# STM32F7x register map
File version: 1.1 AdaCore modified
Registers are 32-bit, read-write, reset 0x0 unless marked. A register's access mark holds for its fields unless they carry their own. Offsets are from the block's base; [hi:lo] are bit positions; {n}, {i} and the like mark numbered series.

## RCC — Reset and clock control
Base 0x40023800
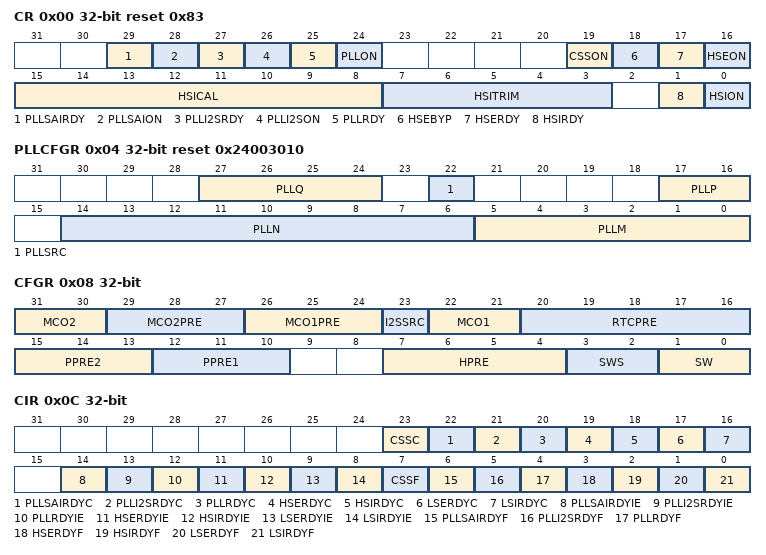
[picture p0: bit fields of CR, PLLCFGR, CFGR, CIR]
0x00 CR access per field reset 0x83 — clock control register
  [29] PLLSAIRDY ro — PLLSAI clock ready flag
  [28] PLLSAION rw — PLLSAI enable
  [27] PLLI2SRDY ro — PLLI2S clock ready flag
  [26] PLLI2SON rw — PLLI2S enable
  [25] PLLRDY ro — Main PLL (PLL) clock ready flag
  [24] PLLON rw — Main PLL (PLL) enable
  [19] CSSON rw — Clock security system enable
  [18] HSEBYP rw — HSE clock bypass
  [17] HSERDY ro — HSE clock ready flag
  [16] HSEON rw — HSE clock enable
  [15:8] HSICAL ro — Internal high-speed clock calibration
  [7:3] HSITRIM rw — Internal high-speed clock trimming
  [1] HSIRDY ro — Internal high-speed clock ready flag
  [0] HSION rw — Internal high-speed clock enable
0x04 PLLCFGR reset 0x24003010 — PLL configuration register
  [27:24] PLLQ — Main PLL (PLL) division factor for USB OTG FS, SDIO and random number generator clocks
  [22] PLLSRC — Main PLL(PLL) and audio PLL (PLLI2S) entry clock source
  [17:16] PLLP — Main PLL (PLL) division factor for main system clock
  [14:6] PLLN — Main PLL (PLL) multiplication factor for VCO
  [5:0] PLLM — Division factor for the main PLL (PLL) and audio PLL (PLLI2S) input clock
0x08 CFGR access per field — clock configuration register
  [31:30] MCO2 rw — Microcontroller clock output 2
  [29:27] MCO2PRE rw — MCO2 prescaler
  [26:24] MCO1PRE rw — MCO1 prescaler
  [23] I2SSRC rw — I2S clock selection
  [22:21] MCO1 rw — Microcontroller clock output 1
  [20:16] RTCPRE rw — HSE division factor for RTC clock
  [15:13] PPRE2 rw — APB high-speed prescaler (APB2)
  [12:10] PPRE1 rw — APB Low speed prescaler (APB1)
  [7:4] HPRE rw — AHB prescaler
  [3:2] SWS ro — System clock switch status
  [1:0] SW rw — System clock switch
0x0C CIR access per field — clock interrupt register
  [23] CSSC wo — Clock security system interrupt clear
  [22] PLLSAIRDYC wo — PLLSAI Ready Interrupt Clear
  [21] PLLI2SRDYC wo — PLLI2S ready interrupt clear
  [20] PLLRDYC wo — Main PLL(PLL) ready interrupt clear
  [19] HSERDYC wo — HSE ready interrupt clear
  [18] HSIRDYC wo — HSI ready interrupt clear
  [17] LSERDYC wo — LSE ready interrupt clear
  [16] LSIRDYC wo — LSI ready interrupt clear
  [14] PLLSAIRDYIE rw — PLLSAI Ready Interrupt Enable
  [13] PLLI2SRDYIE rw — PLLI2S ready interrupt enable
  [12] PLLRDYIE rw — Main PLL (PLL) ready interrupt enable
  [11] HSERDYIE rw — HSE ready interrupt enable
  [10] HSIRDYIE rw — HSI ready interrupt enable
  [9] LSERDYIE rw — LSE ready interrupt enable
  [8] LSIRDYIE rw — LSI ready interrupt enable
  [7] CSSF ro — Clock security system interrupt flag
  [6] PLLSAIRDYF ro — PLLSAI ready interrupt flag
  [5] PLLI2SRDYF ro — PLLI2S ready interrupt flag
  [4] PLLRDYF ro — Main PLL (PLL) ready interrupt flag
  [3] HSERDYF ro — HSE ready interrupt flag
  [2] HSIRDYF ro — HSI ready interrupt flag
  [1] LSERDYF ro — LSE ready interrupt flag
  [0] LSIRDYF ro — LSI ready interrupt flag
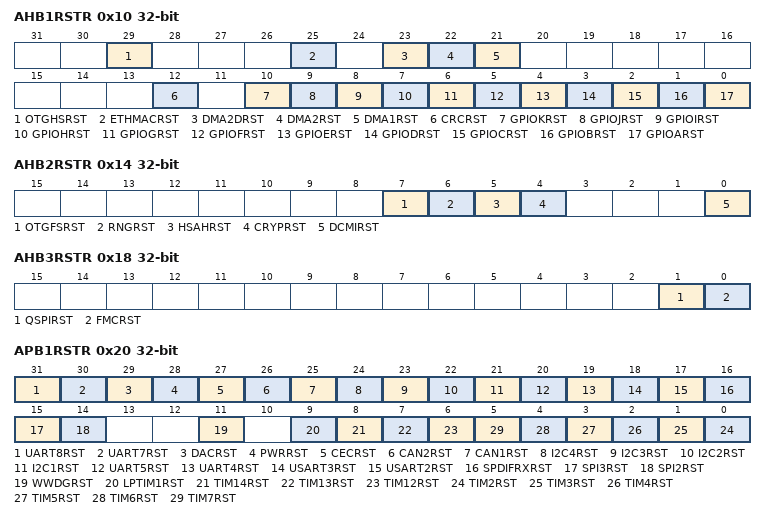
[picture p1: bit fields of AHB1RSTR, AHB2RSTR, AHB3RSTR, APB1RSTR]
0x10 AHB1RSTR — AHB1 peripheral reset register
  [29] OTGHSRST — USB OTG HS module reset
  [25] ETHMACRST — Ethernet MAC reset
  [23] DMA2DRST — DMA2D reset
  [22] DMA2RST — DMA2 reset
  [21] DMA1RST — DMA2 reset
  [12] CRCRST — CRC reset
  [10] GPIOKRST — IO port K reset
  [9] GPIOJRST — IO port J reset
  [8] GPIOIRST — IO port I reset
  [7] GPIOHRST — IO port H reset
  [6] GPIOGRST — IO port G reset
  [5] GPIOFRST — IO port F reset
  [4] GPIOERST — IO port E reset
  [3] GPIODRST — IO port D reset
  [2] GPIOCRST — IO port C reset
  [1] GPIOBRST — IO port B reset
  [0] GPIOARST — IO port A reset
0x14 AHB2RSTR — AHB2 peripheral reset register
  [7] OTGFSRST — USB OTG FS module reset
  [6] RNGRST — Random number generator module reset
  [5] HSAHRST — Hash module reset
  [4] CRYPRST — Cryptographic module reset
  [0] DCMIRST — Camera interface reset
0x18 AHB3RSTR — AHB3 peripheral reset register
  [1] QSPIRST — Quad SPI memory controller reset
  [0] FMCRST — Flexible memory controller module reset
0x20 APB1RSTR — APB1 peripheral reset register
  [31] UART8RST — UART8 reset
  [30] UART7RST — UART7 reset
  [29] DACRST — DAC reset
  [28] PWRRST — Power interface reset
  [27] CECRST — HDMI-CEC reset
  [26] CAN2RST — CAN2 reset
  [25] CAN1RST — CAN1 reset
  [24] I2C4RST — I2C 4 reset
  [23] I2C3RST — I2C3 reset
  [22] I2C2RST — I2C 2 reset
  [21] I2C1RST — I2C 1 reset
  [20] UART5RST — USART 5 reset
  [19] UART4RST — USART 4 reset
  [18] USART3RST — USART 3 reset
  [17] USART2RST — USART 2 reset
  [16] SPDIFRXRST — SPDIF-RX reset
  [15] SPI3RST — SPI 3 reset
  [14] SPI2RST — SPI 2 reset
  [11] WWDGRST — Window watchdog reset
  [9] LPTIM1RST — Low power timer 1 reset
  [8] TIM14RST — TIM14 reset
  [7] TIM13RST — TIM13 reset
  [6] TIM12RST — TIM12 reset
  [n-2] TIM{n}RST (n=2..7) — TIM{n} reset
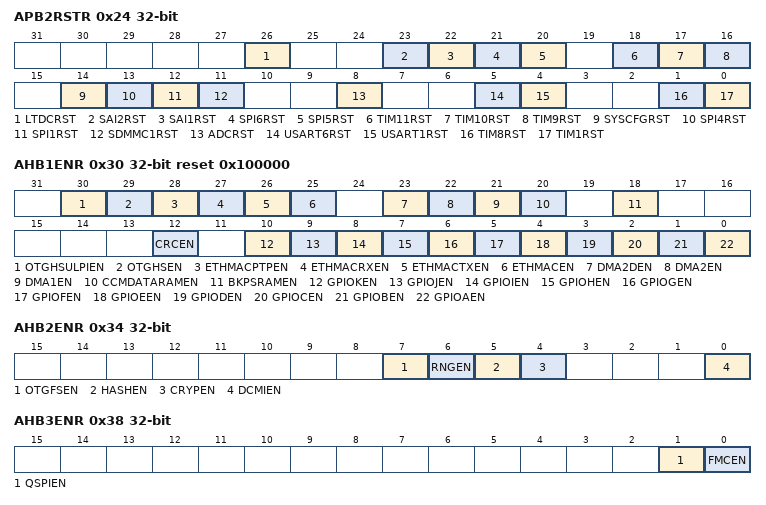
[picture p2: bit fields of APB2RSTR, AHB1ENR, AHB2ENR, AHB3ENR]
0x24 APB2RSTR — APB2 peripheral reset register
  [26] LTDCRST — LTDC reset
  [23] SAI2RST — SAI2 reset
  [22] SAI1RST — SAI1 reset
  [21] SPI6RST — SPI6 reset
  [20] SPI5RST — SPI5 reset
  [18] TIM11RST — TIM11 reset
  [17] TIM10RST — TIM10 reset
  [16] TIM9RST — TIM9 reset
  [14] SYSCFGRST — System configuration controller reset
  [13] SPI4RST — SPI4 reset
  [12] SPI1RST — SPI 1 reset
  [11] SDMMC1RST — SDMMC1 reset
  [8] ADCRST — ADC interface reset (common to all ADCs)
  [5] USART6RST — USART6 reset
  [4] USART1RST — USART1 reset
  [1] TIM8RST — TIM8 reset
  [0] TIM1RST — TIM1 reset
0x30 AHB1ENR reset 0x100000 — AHB1 peripheral clock register
  [30] OTGHSULPIEN — USB OTG HSULPI clock enable
  [29] OTGHSEN — USB OTG HS clock enable
    0=Disabled; 1=Enabled
  [28] ETHMACPTPEN — Ethernet PTP clock enable
    0=Disabled; 1=Enabled
  [27] ETHMACRXEN — Ethernet Reception clock enable
    0=Disabled; 1=Enabled
  [26] ETHMACTXEN — Ethernet Transmission clock enable
    0=Disabled; 1=Enabled
  [25] ETHMACEN — Ethernet MAC clock enable
    0=Disabled; 1=Enabled
  [23] DMA2DEN — DMA2D clock enable
  [22] DMA2EN — DMA2 clock enable
    0=Disabled; 1=Enabled
  [21] DMA1EN — DMA1 clock enable
    0=Disabled; 1=Enabled
  [20] CCMDATARAMEN — CCM data RAM clock enable
    0=Disabled; 1=Enabled
  [18] BKPSRAMEN — Backup SRAM interface clock enable
    0=Disabled; 1=Enabled
  [12] CRCEN — CRC clock enable
    0=Disabled; 1=Enabled
  [10] GPIOKEN — IO port K clock enable
    0=Disabled; 1=Enabled
  [9] GPIOJEN — IO port J clock enable
    0=Disabled; 1=Enabled
  [8] GPIOIEN — IO port I clock enable
    0=Disabled; 1=Enabled
  [7] GPIOHEN — IO port H clock enable
    0=Disabled; 1=Enabled
  [6] GPIOGEN — IO port G clock enable
    0=Disabled; 1=Enabled
  [5] GPIOFEN — IO port F clock enable
    0=Disabled; 1=Enabled
  [4] GPIOEEN — IO port E clock enable
    0=Disabled; 1=Enabled
  [3] GPIODEN — IO port D clock enable
    0=Disabled; 1=Enabled
  [2] GPIOCEN — IO port C clock enable
    0=Disabled; 1=Enabled
  [1] GPIOBEN — IO port B clock enable
    0=Disabled; 1=Enabled
  [0] GPIOAEN — IO port A clock enable
    0=Disabled; 1=Enabled
0x34 AHB2ENR — AHB2 peripheral clock enable register
  [all] fields
    0=Disabled; 1=Enabled
  [7] OTGFSEN — USB OTG FS clock enable
  [6] RNGEN — Random number generator clock enable
  [5] HASHEN — Hash modules clock enable
  [4] CRYPEN — Cryptographic modules clock enable
  [0] DCMIEN — Camera interface enable
0x38 AHB3ENR — AHB3 peripheral clock enable register
  [1] QSPIEN — Quad SPI memory controller clock enable
    0=Disabled; 1=Enabled
  [0] FMCEN — Flexible memory controller module clock enable
    0=Disabled; 1=Enabled
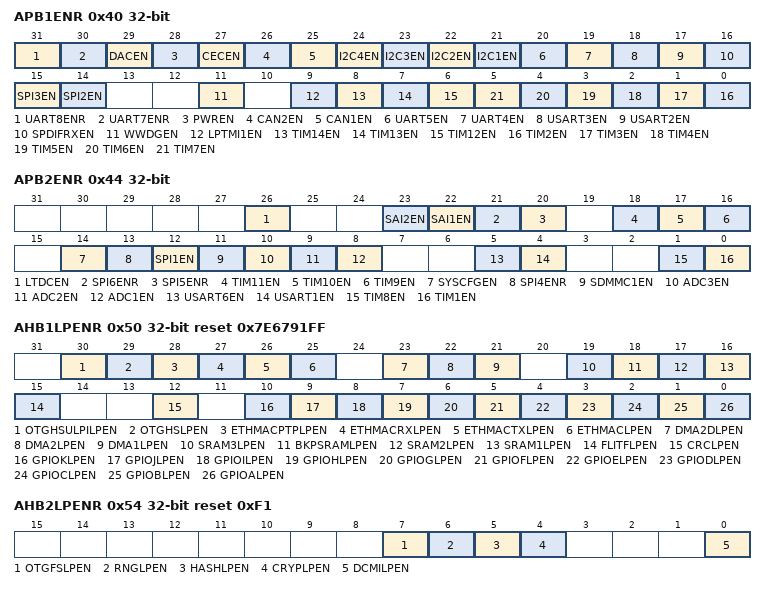
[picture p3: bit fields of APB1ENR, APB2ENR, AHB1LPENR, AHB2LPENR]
0x40 APB1ENR — APB1 peripheral clock enable register
  [all] fields
    0=Disabled; 1=Enabled
  [31] UART8ENR — UART8 clock enable
  [30] UART7ENR — UART7 clock enable
  [29] DACEN — DAC interface clock enable
  [28] PWREN — Power interface clock enable
  [27] CECEN — HDMI-CEN clock enable
  [26] CAN2EN — CAN 2 clock enable
  [25] CAN1EN — CAN 1 clock enable
  [n+20] I2C{n}EN (n=1..4) — I2C{n} clock enable
  [20] UART5EN — UART5 clock enable
  [19] UART4EN — UART4 clock enable
  [18] USART3EN — USART3 clock enable
  [17] USART2EN — USART 2 clock enable
  [16] SPDIFRXEN — SPDIF-RX clock enable
  [15] SPI3EN — SPI3 clock enable
  [14] SPI2EN — SPI2 clock enable
  [11] WWDGEN — Window watchdog clock enable
  [9] LPTMI1EN — Low power timer 1 clock enable
  [8] TIM14EN — TIM14 clock enable
  [7] TIM13EN — TIM13 clock enable
  [6] TIM12EN — TIM12 clock enable
  [n-2] TIM{n}EN (n=2..7) — TIM{n} clock enable
0x44 APB2ENR — APB2 peripheral clock enable register
  [all] fields
    0=Disabled; 1=Enabled
  [26] LTDCEN — LTDC clock enable
  [23] SAI2EN — SAI2 clock enable
  [22] SAI1EN — SAI1 clock enable
  [21] SPI6ENR — SPI6 clock enable
  [20] SPI5ENR — SPI5 clock enable
  [18] TIM11EN — TIM11 clock enable
  [17] TIM10EN — TIM10 clock enable
  [16] TIM9EN — TIM9 clock enable
  [14] SYSCFGEN — System configuration controller clock enable
  [13] SPI4ENR — SPI4 clock enable
  [12] SPI1EN — SPI1 clock enable
  [11] SDMMC1EN — SDMMC1 clock enable
  [10] ADC3EN — ADC3 clock enable
  [9] ADC2EN — ADC2 clock enable
  [8] ADC1EN — ADC1 clock enable
  [5] USART6EN — USART6 clock enable
  [4] USART1EN — USART1 clock enable
  [1] TIM8EN — TIM8 clock enable
  [0] TIM1EN — TIM1 clock enable
0x50 AHB1LPENR reset 0x7E6791FF — AHB1 peripheral clock enable in low power mode register
  [30] OTGHSULPILPEN — USB OTG HS ULPI clock enable during Sleep mode
  [29] OTGHSLPEN — USB OTG HS clock enable during Sleep mode
  [28] ETHMACPTPLPEN — Ethernet PTP clock enable during Sleep mode
  [27] ETHMACRXLPEN — Ethernet reception clock enable during Sleep mode
  [26] ETHMACTXLPEN — Ethernet transmission clock enable during Sleep mode
  [25] ETHMACLPEN — Ethernet MAC clock enable during Sleep mode
  [23] DMA2DLPEN — DMA2D clock enable during Sleep mode
  [22] DMA2LPEN — DMA2 clock enable during Sleep mode
  [21] DMA1LPEN — DMA1 clock enable during Sleep mode
  [19] SRAM3LPEN — SRAM 3 interface clock enable during Sleep mode
  [18] BKPSRAMLPEN — Backup SRAM interface clock enable during Sleep mode
  [17] SRAM2LPEN — SRAM 2 interface clock enable during Sleep mode
  [16] SRAM1LPEN — SRAM 1interface clock enable during Sleep mode
  [15] FLITFLPEN — Flash interface clock enable during Sleep mode
  [12] CRCLPEN — CRC clock enable during Sleep mode
  [10] GPIOKLPEN — IO port K clock enable during Sleep mode
  [9] GPIOJLPEN — IO port J clock enable during Sleep mode
  [8] GPIOILPEN — IO port I clock enable during Sleep mode
  [7] GPIOHLPEN — IO port H clock enable during Sleep mode
  [6] GPIOGLPEN — IO port G clock enable during Sleep mode
  [5] GPIOFLPEN — IO port F clock enable during Sleep mode
  [4] GPIOELPEN — IO port E clock enable during Sleep mode
  [3] GPIODLPEN — IO port D clock enable during Sleep mode
  [2] GPIOCLPEN — IO port C clock enable during Sleep mode
  [1] GPIOBLPEN — IO port B clock enable during Sleep mode
  [0] GPIOALPEN — IO port A clock enable during sleep mode
0x54 AHB2LPENR reset 0xF1 — AHB2 peripheral clock enable in low power mode register
  [7] OTGFSLPEN — USB OTG FS clock enable during Sleep mode
  [6] RNGLPEN — Random number generator clock enable during Sleep mode
  [5] HASHLPEN — Hash modules clock enable during Sleep mode
  [4] CRYPLPEN — Cryptography modules clock enable during Sleep mode
  [0] DCMILPEN — Camera interface enable during Sleep mode
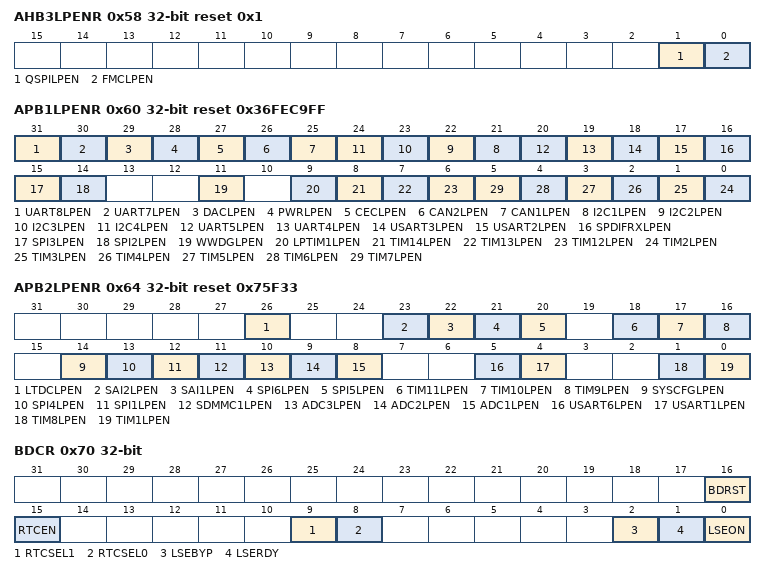
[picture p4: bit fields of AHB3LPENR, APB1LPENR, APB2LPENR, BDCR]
0x58 AHB3LPENR reset 0x1 — AHB3 peripheral clock enable in low power mode register
  [1] QSPILPEN — Quand SPI memory controller clock enable during Sleep mode
  [0] FMCLPEN — Flexible memory controller module clock enable during Sleep mode
0x60 APB1LPENR reset 0x36FEC9FF — APB1 peripheral clock enable in low power mode register
  [31] UART8LPEN — UART8 clock enable during Sleep mode
  [30] UART7LPEN — UART7 clock enable during Sleep mode
  [29] DACLPEN — DAC interface clock enable during Sleep mode
  [28] PWRLPEN — Power interface clock enable during Sleep mode
  [27] CECLPEN — HDMI-CEN clock enable during Sleep mode
  [26] CAN2LPEN — CAN 2 clock enable during Sleep mode
  [25] CAN1LPEN — CAN 1 clock enable during Sleep mode
  [n+20] I2C{n}LPEN (n=1..4) — I2C{n} clock enable during Sleep mode
  [20] UART5LPEN — UART5 clock enable during Sleep mode
  [19] UART4LPEN — UART4 clock enable during Sleep mode
  [18] USART3LPEN — USART3 clock enable during Sleep mode
  [17] USART2LPEN — USART2 clock enable during Sleep mode
  [16] SPDIFRXLPEN — SPDIF-RX clock enable during sleep mode
  [15] SPI3LPEN — SPI3 clock enable during Sleep mode
  [14] SPI2LPEN — SPI2 clock enable during Sleep mode
  [11] WWDGLPEN — Window watchdog clock enable during Sleep mode
  [9] LPTIM1LPEN — low power timer 1 clock enable during Sleep mode
  [8] TIM14LPEN — TIM14 clock enable during Sleep mode
  [7] TIM13LPEN — TIM13 clock enable during Sleep mode
  [6] TIM12LPEN — TIM12 clock enable during Sleep mode
  [n-2] TIM{n}LPEN (n=2..7) — TIM{n} clock enable during Sleep mode
0x64 APB2LPENR reset 0x75F33 — APB2 peripheral clock enabled in low power mode register
  [26] LTDCLPEN — LTDC clock enable during sleep mode
  [23] SAI2LPEN — SAI2 clock enable during sleep mode
  [22] SAI1LPEN — SAI1 clock enable during sleep mode
  [21] SPI6LPEN — SPI 6 clock enable during Sleep mode
  [20] SPI5LPEN — SPI 5 clock enable during Sleep mode
  [18] TIM11LPEN — TIM11 clock enable during Sleep mode
  [17] TIM10LPEN — TIM10 clock enable during Sleep mode
  [16] TIM9LPEN — TIM9 clock enable during sleep mode
  [14] SYSCFGLPEN — System configuration controller clock enable during Sleep mode
  [13] SPI4LPEN — SPI 4 clock enable during Sleep mode
  [12] SPI1LPEN — SPI 1 clock enable during Sleep mode
  [11] SDMMC1LPEN — SDMMC1 clock enable during Sleep mode
  [10] ADC3LPEN — ADC 3 clock enable during Sleep mode
  [9] ADC2LPEN — ADC2 clock enable during Sleep mode
  [8] ADC1LPEN — ADC1 clock enable during Sleep mode
  [5] USART6LPEN — USART6 clock enable during Sleep mode
  [4] USART1LPEN — USART1 clock enable during Sleep mode
  [1] TIM8LPEN — TIM8 clock enable during Sleep mode
  [0] TIM1LPEN — TIM1 clock enable during Sleep mode
0x70 BDCR access per field — Backup domain control register
  [16] BDRST rw — Backup domain software reset
  [15] RTCEN rw — RTC clock enable
  [9] RTCSEL1 rw — RTC clock source selection
  [8] RTCSEL0 rw — RTC clock source selection
  [2] LSEBYP rw — External low-speed oscillator bypass
  [1] LSERDY ro — External low-speed oscillator ready
  [0] LSEON rw — External low-speed oscillator enable
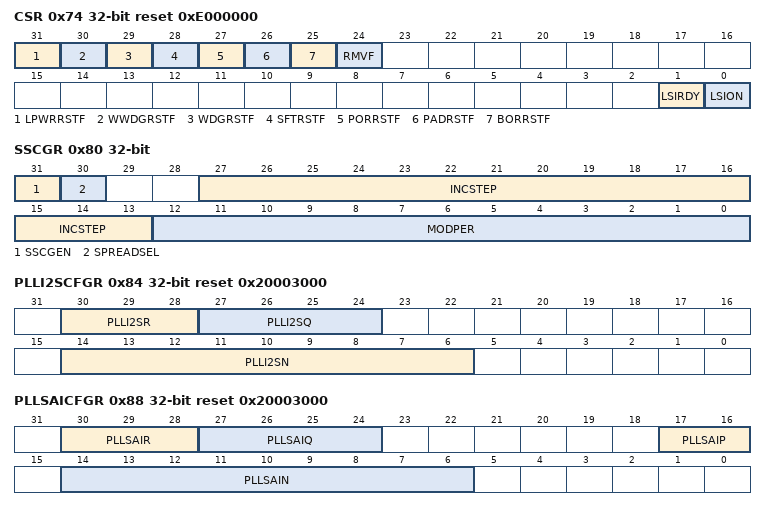
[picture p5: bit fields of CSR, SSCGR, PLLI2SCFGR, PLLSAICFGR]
0x74 CSR access per field reset 0xE000000 — clock control & status register
  [31] LPWRRSTF rw — Low-power reset flag
  [30] WWDGRSTF rw — Window watchdog reset flag
  [29] WDGRSTF rw — Independent watchdog reset flag
  [28] SFTRSTF rw — Software reset flag
  [27] PORRSTF rw — POR/PDR reset flag
  [26] PADRSTF rw — PIN reset flag
  [25] BORRSTF rw — BOR reset flag
  [24] RMVF rw — Remove reset flag
  [1] LSIRDY ro — Internal low-speed oscillator ready
  [0] LSION rw — Internal low-speed oscillator enable
0x80 SSCGR — spread spectrum clock generation register
  [31] SSCGEN — Spread spectrum modulation enable
  [30] SPREADSEL — Spread Select
  [27:13] INCSTEP — Incrementation step
  [12:0] MODPER — Modulation period
0x84 PLLI2SCFGR reset 0x20003000 — PLLI2S configuration register
  [30:28] PLLI2SR — PLLI2S division factor for I2S clocks
  [27:24] PLLI2SQ — PLLI2S division factor for SAI1 clock
  [14:6] PLLI2SN — PLLI2S multiplication factor for VCO
0x88 PLLSAICFGR reset 0x20003000 — PLL configuration register
  [30:28] PLLSAIR — PLLSAI division factor for LCD clock
  [27:24] PLLSAIQ — PLLSAI division factor for SAI clock
  [17:16] PLLSAIP — PLLSAI division factor for 48MHz clock
  [14:6] PLLSAIN — PLLSAI division factor for VCO
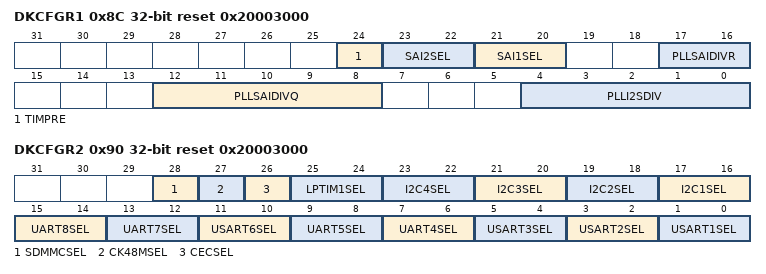
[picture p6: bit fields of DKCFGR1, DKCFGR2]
0x8C DKCFGR1 reset 0x20003000 — dedicated clocks configuration register
  [24] TIMPRE — Timers clocks prescalers selection
  [23:22] SAI2SEL — SAI2 clock source selection
  [21:20] SAI1SEL — SAI1 clock source selection
  [17:16] PLLSAIDIVR — division factor for LCD_CLK
  [12:8] PLLSAIDIVQ — PLLSAI division factor for SAI1 clock
  [4:0] PLLI2SDIV — PLLI2S division factor for SAI1 clock
0x90 DKCFGR2 reset 0x20003000 — dedicated clocks configuration register
  [28] SDMMCSEL — SDMMC clock source selection
  [27] CK48MSEL — 48MHz clock source selection
  [26] CECSEL — HDMI-CEC clock source selection
  [25:24] LPTIM1SEL — Low power timer 1 clock source selection
  [2n+15:2n+14] I2C{n}SEL (n=1..4) — I2C{n} clock source selection
  [15:14] UART8SEL — UART 8 clock source selection
  [13:12] UART7SEL — UART 7 clock source selection
  [11:10] USART6SEL — USART 6 clock source selection
  [9:8] UART5SEL — UART 5 clock source selection
  [7:6] UART4SEL — UART 4 clock source selection
  [5:4] USART3SEL — USART 3 clock source selection
  [3:2] USART2SEL — USART 2 clock source selection
  [1:0] USART1SEL — USART 1 clock source selection
